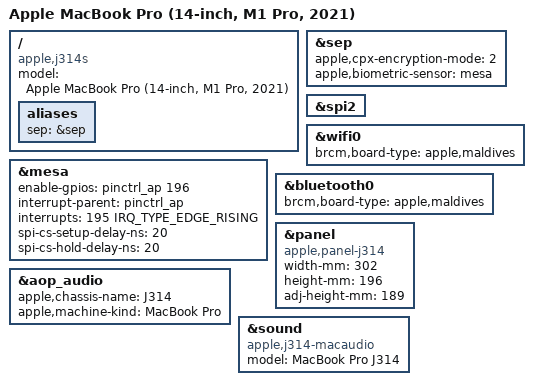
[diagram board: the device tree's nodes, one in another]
// SPDX-License-Identifier: GPL-2.0+ OR MIT
/*
 * MacBook Pro (14-inch, M1 Pro, 2021)
 *
 * target-type: J314s
 *
 * Copyright The Asahi Linux Contributors
 */

/dts-v1/;

#include "t6000.dtsi"
#include "t600x-j314-j316.dtsi"

/ {
	compatible = "apple,j314s", "apple,t6000", "apple,arm-platform";
	model = "Apple MacBook Pro (14-inch, M1 Pro, 2021)";

	aliases {
		/*
		 * m1n1 (kboot dt_set_sep) keys off this alias: it adds the
		 * "sepfw" reserved-memory region and copies the local-policy
		 * and iBoot manifests into the SEP node for the cold boot.
		 */
		sep = &sep;
	};
};

&sep {
	status = "okay";
	/*
	 * The J314s ADT's /defaults cpx-encryption-mode, which the 13.5 key
	 * store's SET_ENV carries (AppleKeyStore::init_sep_endpoint). A static
	 * board value, read by sepd; the driver itself does not use it.
	 */
	apple,cpx-encryption-mode = <2>;
	/* The Touch ID sensor the SEP drives through the AP (apple-mesa). */
	apple,biometric-sensor = <&mesa>;
};

/*
 * Mesa fingerprint sensor, from the J314s platform device tree
 * (/arm-io/spi2/mesa): function-mesa_pwr = gpio0 GPIO(0xc4, 0x101), i.e.
 * pin 196, active high as on J313/J316s; interrupts = <195 3> on gpio0 for
 * data-ready. The ADT trigger encoding is not Linux's (the keyboard's ADT
 * value 1 is IRQ_TYPE_LEVEL_LOW), so the rising edge used here is the
 * reference driver's observed behaviour, not a decode. The ADT also gives
 * sensor-id 0x3352, 8 MHz, CPOL=1 and a 20 ns CS delay.
 *
 * Needs spi-apple's hardware CS timing (installed only on a bus with an
 * apple,mesa-fingerprint child); apple-mesa refuses to probe without it.
 */
&spi2 {
	status = "okay";
};

&mesa {
	status = "okay";
	enable-gpios = <&pinctrl_ap 196 GPIO_ACTIVE_HIGH>;
	interrupt-parent = <&pinctrl_ap>;
	interrupts = <195 IRQ_TYPE_EDGE_RISING>;
	spi-cs-setup-delay-ns = <20>;
	spi-cs-hold-delay-ns = <20>;
};

&wifi0 {
	brcm,board-type = "apple,maldives";
};

&bluetooth0 {
	brcm,board-type = "apple,maldives";
};

&panel {
	compatible = "apple,panel-j314", "apple,panel-mini-led", "apple,panel";
	width-mm = <302>;
	height-mm = <196>;
	adj-height-mm = <189>;
};

&aop_audio {
	apple,chassis-name = "J314";
	apple,machine-kind = "MacBook Pro";
};

&sound {
	compatible = "apple,j314-macaudio", "apple,macaudio";
	model = "MacBook Pro J314";
};
